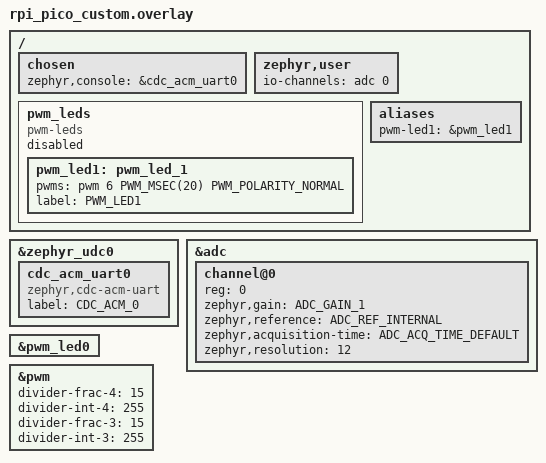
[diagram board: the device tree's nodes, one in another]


/ {
    chosen {
        zephyr,console = &cdc_acm_uart0;
    };
    zephyr,user {
        io-channels = <&adc 0>;
        io-channel-names = "VR0";
    };
	pwm_leds {
		compatible = "pwm-leds";
		status = "disabled";
		pwm_led1: pwm_led_1 {
			pwms = <&pwm 6 PWM_MSEC(20) PWM_POLARITY_NORMAL>;
			label = "PWM_LED1";
		};
	};

	aliases {
		pwm-led1 = &pwm_led1;
	};
	
};

&zephyr_udc0 {
    cdc_acm_uart0: cdc_acm_uart0 {
        compatible = "zephyr,cdc-acm-uart";
        label = "CDC_ACM_0";
    };
};

&adc {
	#address-cells = <1>;
	#size-cells = <0>;

	channel@0 {
		reg = <0>;
		zephyr,gain = "ADC_GAIN_1";
		zephyr,reference = "ADC_REF_INTERNAL";
		zephyr,acquisition-time = <ADC_ACQ_TIME_DEFAULT>;
		zephyr,resolution = <12>;
	};
};

&pwm_led0 {
	status = "okay";
};

&pwm_led1 {
	status = "okay";
};

&pwm {
	status = "okay";
	divider-frac-4 = <15>;
	divider-int-4 = <255>;
	divider-frac-3 = <15>;
	divider-int-3 = <255>;
};
